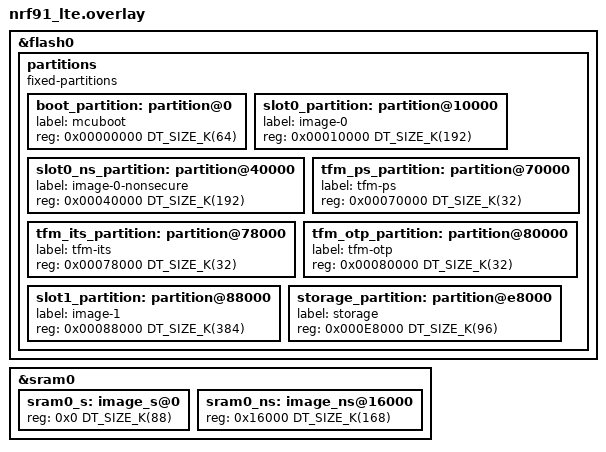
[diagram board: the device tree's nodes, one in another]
/*
 * Copyright (c) 2026 Nordic Semiconductor ASA
 *
 * SPDX-License-Identifier: LicenseRef-Nordic-5-Clause
 */

/*
 * LTE-optimized TF-M partition layout for nRF91 Series
 *
 * nRF91 Series has 1024 kB of flash and 256 kB of SRAM.
 * TrustZone flash region alignment: 32 kB (SPU-based)
 * TrustZone RAM region alignment:    8 kB
 * Flash erase-block-size:            4 kB
 *
 * Optimized for cellular IoT applications with:
 * - MCUboot for FOTA over LTE
 * - Medium TF-M secure partition (enough for TLS/DTLS crypto)
 * - Protected Storage for TLS credentials/certificates
 * - ITS for PSK keys and device identity
 * - Large NS partition for modem library + LTE stack + application
 * - Storage for LwM2M / nRF Cloud state
 *
 * Note: The nRF91 modem firmware is updated separately via
 * nrfjprog/nrfutil and is not part of this flash layout.
 * The modem library (nrf_modem) runs in NS and needs ~64 kB SRAM.
 *
 * Suitable for: asset trackers, smart meters, environmental sensors,
 *               LwM2M devices, nRF Cloud connected devices
 *
 * Applies to boards: nrf9160dk/nrf9160/ns, nrf9161dk/nrf9161/ns,
 *                    nrf9151dk/nrf9151/ns
 */

&flash0 {
	partitions {
		compatible = "fixed-partitions";
		#address-cells = <1>;
		#size-cells = <1>;

		/*
		 * Flash layout (S/NS boundaries 32 kB aligned):
		 *
		 * 0x00000000  MCUboot bootloader        (64 kB = 2 × 32 kB)
		 * 0x00010000  Primary slot:
		 *   0x00010000  TF-M secure image       (192 kB = 6 × 32 kB)
		 *   0x00040000  Non-secure LTE app       (192 kB = 6 × 32 kB)
		 * 0x00070000  TF-M PS                    (32 kB = 1 × 32 kB)
		 * 0x00078000  TF-M ITS                   (32 kB = 1 × 32 kB)
		 * 0x00080000  TF-M OTP / NV counters     (32 kB = 1 × 32 kB)
		 * 0x00088000  Secondary slot            (384 kB)
		 * 0x000E8000  Non-secure storage         (96 kB)
		 *
		 * Primary slot = 192 + 192 = 384 kB = Secondary slot.
		 * Larger NS storage for LwM2M/Cloud state persistence.
		 */

		boot_partition: partition@0 {
			label = "mcuboot";
			reg = <0x00000000 DT_SIZE_K(64)>;
		};

		slot0_partition: partition@10000 {
			label = "image-0";
			reg = <0x00010000 DT_SIZE_K(192)>;
		};

		slot0_ns_partition: partition@40000 {
			label = "image-0-nonsecure";
			reg = <0x00040000 DT_SIZE_K(192)>;
		};

		tfm_ps_partition: partition@70000 {
			label = "tfm-ps";
			reg = <0x00070000 DT_SIZE_K(32)>;
		};

		tfm_its_partition: partition@78000 {
			label = "tfm-its";
			reg = <0x00078000 DT_SIZE_K(32)>;
		};

		tfm_otp_partition: partition@80000 {
			label = "tfm-otp";
			reg = <0x00080000 DT_SIZE_K(32)>;
		};

		slot1_partition: partition@88000 {
			label = "image-1";
			reg = <0x00088000 DT_SIZE_K(384)>;
		};

		storage_partition: partition@e8000 {
			label = "storage";
			reg = <0x000E8000 DT_SIZE_K(96)>;
		};
	};
};

&sram0 {
	sram0_s: image_s@0 {
		#address-cells = <1>;
		#size-cells = <1>;
		/* 88 kB secure — 8 kB aligned */
		reg = <0x0 DT_SIZE_K(88)>;
		ranges = <0x0 0x0 DT_SIZE_K(88)>;
	};

	sram0_ns: image_ns@16000 {
		#address-cells = <1>;
		#size-cells = <1>;
		/*
		 * 168 kB non-secure — modem library needs ~64 kB,
		 * leaves ~104 kB for LTE application
		 */
		reg = <0x16000 DT_SIZE_K(168)>;
		ranges = <0x0 0x16000 DT_SIZE_K(168)>;
	};
};
